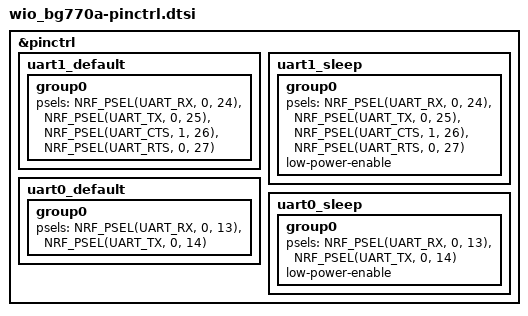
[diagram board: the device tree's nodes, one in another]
/*
 * Copyright (c) Seeed K.K.
 * SPDX-License-Identifier: Apache-2.0
 */

&pinctrl {
	uart1_default: uart1_default {
		group0 {
			psels = <NRF_PSEL(UART_RX, 0, 24)>,
				<NRF_PSEL(UART_TX, 0, 25)>,
				<NRF_PSEL(UART_CTS, 1, 26)>,
				<NRF_PSEL(UART_RTS, 0, 27)>;
		};
	};

	uart1_sleep: uart1_sleep {
		group0 {
			psels = <NRF_PSEL(UART_RX, 0, 24)>,
				<NRF_PSEL(UART_TX, 0, 25)>,
				<NRF_PSEL(UART_CTS, 1, 26)>,
				<NRF_PSEL(UART_RTS, 0, 27)>;

			low-power-enable;
		};
	};

	uart0_default: uart0_default {
		group0 {
			psels = <NRF_PSEL(UART_RX, 0, 13)>,
				<NRF_PSEL(UART_TX, 0, 14)>;
		};
	};

	uart0_sleep: uart0_sleep {
		group0 {
			psels = <NRF_PSEL(UART_RX, 0, 13)>,
				<NRF_PSEL(UART_TX, 0, 14)>;

			low-power-enable;
		};
	};
};
